# STM32H503xx register map
File version: 1.0
Registers are 32-bit, read-write, reset 0x0 unless marked. A register's access mark holds for its fields unless they carry their own. Offsets are from the block's base; [hi:lo] are bit positions; lines under a group give offsets from that group; 'fields as' and 'values as' point back to an identical list.

## FLASH — FLASH Registers
Base 0x40022000
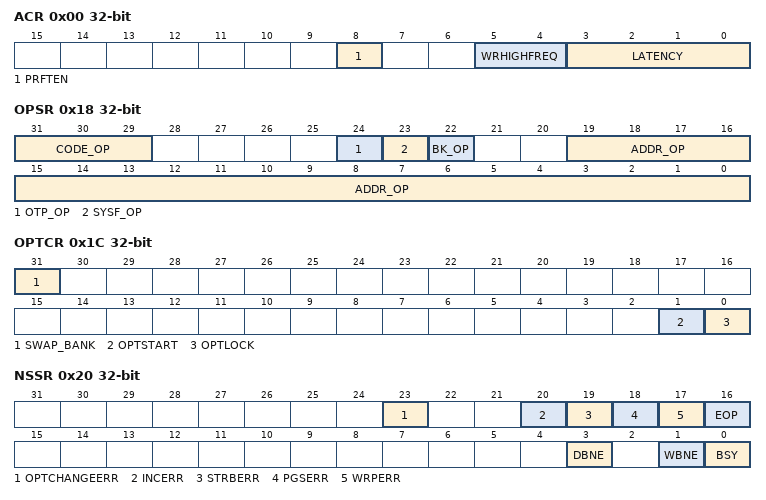
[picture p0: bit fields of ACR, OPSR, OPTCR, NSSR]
0x00 ACR — FLASH access control register
  [8] PRFTEN — Prefetch enable
  [5:4] WRHIGHFREQ — Flash signal delay
  [3:0] LATENCY
    0=FLASH zero wait state; 1=FLASH one wait state; 2=FLASH two wait states; 3=FLASH three wait states; 4=FLASH four wait states; 5=FLASH five wait states; 6=FLASH six wait state; 7=FLASH Seven wait states; 8=FLASH Eight wait states; 9=FLASH nine wait states; 10=FLASH ten wait states; 11=FLASH eleven wait states; 12=FLASH twelve wait states; 13=FLASH thirteen wait states; 14=FLASH fourteen wait states; 15=FLASH fifteen wait states
0x04 NSKEYR — FLASH non-secure key register
0x0C OPTKEYR — FLASH option key register
0x18 OPSR — FLASH OPSR register
  [31:29] CODE_OP — Flash memory operation code
  [24] OTP_OP — Operation in OTP area interrupted
  [23] SYSF_OP — Operation in System Flash interrupted
  [22] BK_OP — Interrupted operation bank
  [19:0] ADDR_OP — Interrupted operation address
0x1C OPTCR — Flash Option Control Register
  [31] SWAP_BANK — Bank swapping option configuration bit
  [1] OPTSTART — Option byte start change option configuration bit
  [0] OPTLOCK — FLASH_OPTCR lock option configuration bit
0x20 NSSR — FLASH non-secure status register
  [23] OPTCHANGEERR — Option byte change error flag
  [20] INCERR — Inconsistency error flag
  [19] STRBERR — Strobe error flag
  [18] PGSERR — Programming sequence error flag
  [17] WRPERR — Write protection error flag
  [16] EOP — End-of-program flag
  [3] DBNE — Data buffer not empty flag
  [1] WBNE — Write buffer not empty flag
  [0] BSY — Busy flag
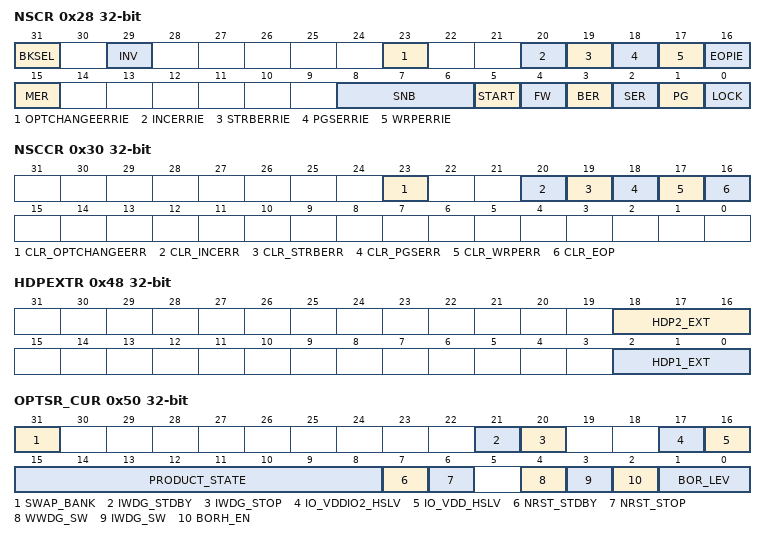
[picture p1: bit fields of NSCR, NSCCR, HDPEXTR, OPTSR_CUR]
0x28 NSCR — FLASH non-secure control register
  [31] BKSEL — Bank selector
  [29] INV — Flash Security State Invert
  [23] OPTCHANGEERRIE — Option byte change error interrupt enable bit
  [20] INCERRIE — Inconsistency error interrupt enable bit
  [19] STRBERRIE — Strobe error interrupt enable bit
  [18] PGSERRIE — Programming sequence error interrupt enable bit
  [17] WRPERRIE — Write protection error interrupt enable bit
  [16] EOPIE — End-of-operation interrupt control bit
  [15] MER — Mass erase
  [8:6] SNB — Sector erase selection number
  [5] START — Erase start control bit
  [4] FW — Write forcing control bit
  [3] BER — Bank erase request
  [2] SER — Sector erase request
  [1] PG — Programming control bit
  [0] LOCK — Configuration lock bit
0x30 NSCCR — FLASH non-secure clear control register
  [23] CLR_OPTCHANGEERR — Option byte change error clear bit
  [20] CLR_INCERR — INCERR flag clear bit
  [19] CLR_STRBERR — STRBERR flag clear bit
  [18] CLR_PGSERR — PGSERR flag clear bit
  [17] CLR_WRPERR — WRPERR flag clear bit
  [16] CLR_EOP — EOP flag clear bit
0x3C PRIVCFGR — FLASH privilege configuration register
  [1] NSPRIV — Privilege protection for non-secure registers
0x48 HDPEXTR — FLASH HDP extension register
  [18:16] HDP2_EXT — HDP area extension in 8kB sectors in bank 2
  [2:0] HDP1_EXT — HDP area extension in 8kB sectors in bank 1
0x50 OPTSR_CUR — FLASH option status current register
  [31] SWAP_BANK — Bank swapping option bit
  [21] IWDG_STDBY — Independent watchdog counter freeze in Standby mode
  [20] IWDG_STOP — Independent watchdog counter freeze in Stop mode
  [17] IO_VDDIO2_HSLV — VDDIO2 I/O high-speed at low-voltage option bit
  [16] IO_VDD_HSLV — VDD I/O high-speed at low-voltage option bit
  [15:8] PRODUCT_STATE — Life state code option byte
  [7] NRST_STDBY — Standby mode entry reset option bit
  [6] NRST_STOP — Stop mode entry reset option bit
  [4] WWDG_SW — WWDG control mode option bit
  [3] IWDG_SW — IWDG control mode option bit
  [2] BORH_EN — Brownout high enable configuration bit
  [1:0] BOR_LEV — Brownout level option bit
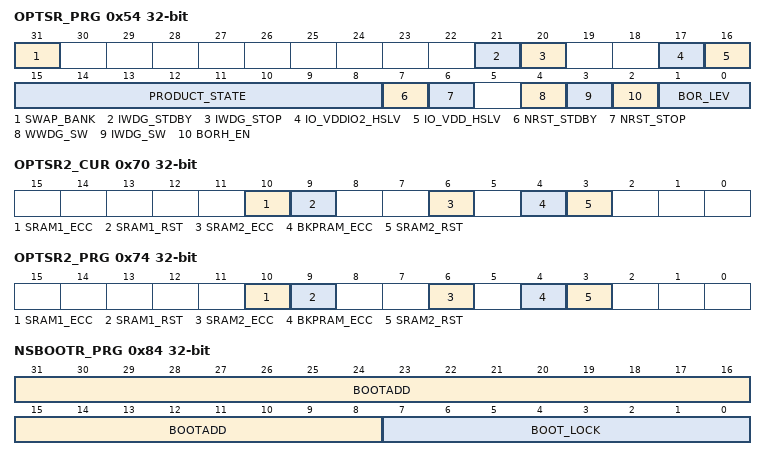
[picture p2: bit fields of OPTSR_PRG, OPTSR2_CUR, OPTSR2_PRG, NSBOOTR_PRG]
0x54 OPTSR_PRG — FLASH option status to program register
  fields as OPTSR_CUR
0x60 NSEPOCHR_CUR — FLASH non-secure epoch current register
0x64 NSEPOCHR_PRG — FLASH non-secure epoch to program register
0x70 OPTSR2_CUR — FLASH option status current register 2
  [10] SRAM1_ECC — SRAM1 ECC detection and correction disable
  [9] SRAM1_RST — SRAM1 erase upon a system reset
  [6] SRAM2_ECC — SRAM2 ECC detection and correction disable
  [4] BKPRAM_ECC — Backup RAM ECC detection and correction enable
  [3] SRAM2_RST — SRAM2 erased when a system reset occurs
0x74 OPTSR2_PRG — FLASH option status to program register 2
  fields as OPTSR2_CUR
0x80 NSBOOTR_CUR — FLASH non-secure unique boot entry current register
0x84 NSBOOTR_PRG — FLASH non-secure unique boot entry to program register
  [31:8] BOOTADD — Boot address
  [7:0] BOOT_LOCK
0x90 OTPBLR_CUR — FLASH OTP block lock current register
0x94 OTPBLR_PRG — FLASH OTP block Lock to program register
0xC0 PRIVBB1R1 — FLASH privilege block-based bank 1 register 1
0xE8 WRP1R_CUR — FLASH write sector group protection current register for bank1
0xEC WRP1R_PRG — FLASH write sector group protection to program register for bank1
0xF8 HDP1R_CUR — FLASH HDP configuration current register for bank1
0xFC HDP1R_PRG — FLASH HDP configuration to program register for bank1
0x100 ECCCORR — FLASH ECC correction register
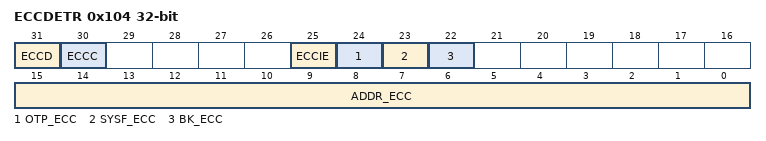
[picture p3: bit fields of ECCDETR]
0x104 ECCDETR — FLASH ECC detection register
  [31] ECCD — ECC detection
  [30] ECCC — ECC correction
  [25] ECCIE — ECC correction interrupt enable
  [24] OTP_ECC — Flash OTP ECC fail
  [23] SYSF_ECC — System Flash ECC fail
  [22] BK_ECC — ECC fail bank
  [15:0] ADDR_ECC — ECC fail address
0x108 ECCDR — FLASH ECC data register
  [15:0] FAIL_DATA — ECC fail data
0x1C0 PRIVBB2R1 — FLASH privilege block-based bank 2 register 1
0x1E8 WRP2R_CUR — FLASH write sector group protection current register for bank2
0x1EC WRP2R_PRG — FLASH write sector group protection to program register for bank2
0x1F8 HDP2R_CUR — FLASH HDP configuration current register for bank2
0x1FC HDP2R_PRG — FLASH HDP configuration to program register for bank2
